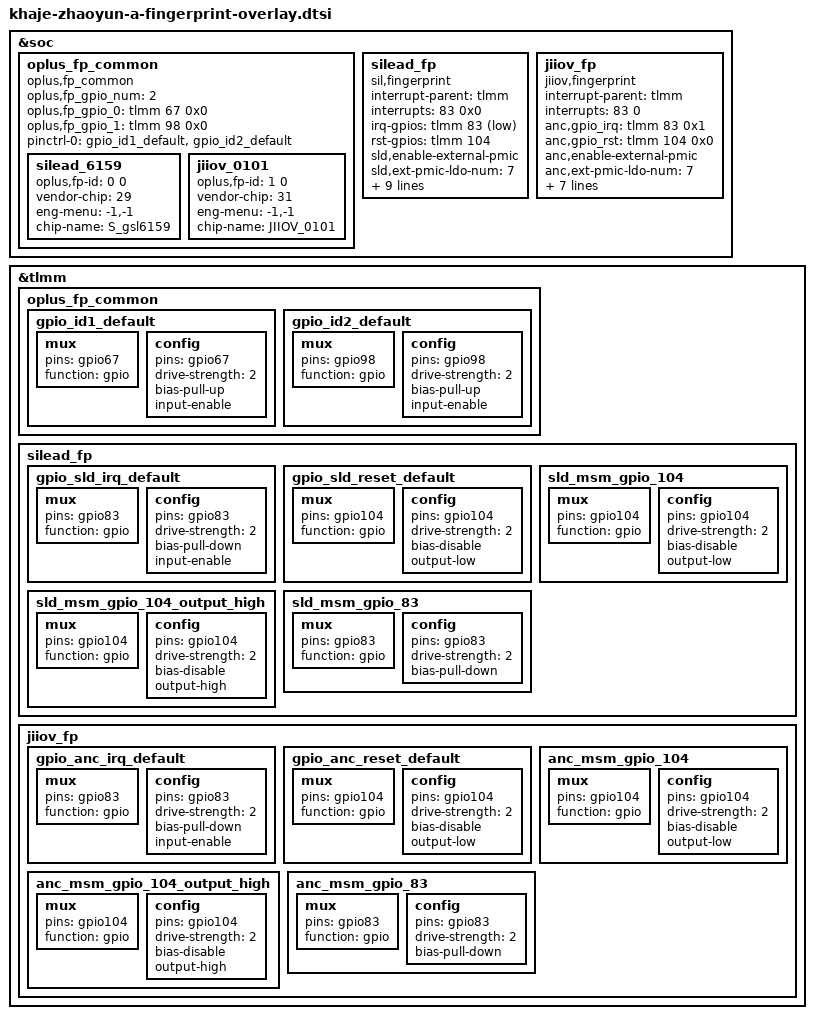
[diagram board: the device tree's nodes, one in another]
// SPDX-License-Identifier: GPL-2.0-only
/*
 * Copyright (C) 2018-2020 Oplus. All rights reserved.
 */


&soc {
	oplus_fp_common {
		status = "okay";
		compatible = "oplus,fp_common";
		oplus,fp_gpio_num = <2>;
		oplus,fp_gpio_0 = <&tlmm 67 0x0>;
		oplus,fp_gpio_1 = <&tlmm 98 0x0>;
		pinctrl-names = "default";
		pinctrl-0 = <&gpio_id1_default &gpio_id2_default>;
		silead_6159 {
			oplus,fp-id = <0 0>; /* fp id mapping table */
			vendor-chip = <29>; /* please refer to the struct fp_vendor_t in oppo_fp_commmon.n */
			eng-menu = "-1,-1"; /* represents SNR, inclination test item in engineer menu, and 0/1 means off/on */
			chip-name = "S_gsl6159";  /* /proc/fp_id, will be displayed in engineer menu  */
		};
		jiiov_0101 {
			oplus,fp-id = <1 0>; // fp id mapping table
			vendor-chip = <31>; // please refer to the struct fp_vendor_t in oplus_fp_commmon.n
			eng-menu = "-1,-1"; // represents SNR, inclination test item in engineer menu, and 0/1 means off/on
			chip-name = "JIIOV_0101";  // /proc/fp_id, will be displayed in engineer menu
		};
	};
};

&tlmm {
	oplus_fp_common {
		gpio_id1_default: gpio_id1_default {
			mux {
				pins = "gpio67";
				function = "gpio";
			};
			config {
				pins = "gpio67";
				drive-strength = <2>;
				bias-pull-up;
				input-enable;
			};
		};
		gpio_id2_default: gpio_id2_default {
			mux {
				pins = "gpio98";
				function = "gpio";
			};
			config {
				pins = "gpio98";
				drive-strength = <2>;
				bias-pull-up;
				input-enable;
			};
		};
	};
};



&soc {
	silead_fp {
		status = "okay";
		compatible = "sil,fingerprint";
		interrupt-parent = <&tlmm>;
		interrupts = <83 0x0>;
		irq-gpios = <&tlmm 83 0x1>;
		rst-gpios = <&tlmm 104 0x0>;
		//avdd-supply = <&L7P>;
		sld,enable-external-pmic;
		sld,ext-pmic-ldo-num = <7>;
		sld,ext-pmic-ldo-mv-max = <3000>;
		sld,ext-pmic-ldo-mv-min = <0>;
		spi-max-frequency = <4800000>;
		qcom,qup-id = <6>;
		pinctrl-names = "default", "sld_reset_reset", "sld_reset_active", "sld_irq_active";
		pinctrl-0 = <&gpio_sld_irq_default>, <&gpio_sld_reset_default>;
		pinctrl-1 = <&sld_msm_gpio_104>;
		pinctrl-2 = <&sld_msm_gpio_104_output_high>;
		pinctrl-3 = <&sld_msm_gpio_83>;
	};
};


&tlmm {
	silead_fp {
		gpio_sld_irq_default: gpio_sld_irq_default {
			mux {
				pins = "gpio83";
				function = "gpio";
			};
			config {
				pins = "gpio83";
				drive-strength = <2>;
				bias-pull-down;
				input-enable;
			};
		};
		gpio_sld_reset_default: gpio_sld_reset_default {
			mux {
				pins = "gpio104";
				function = "gpio";
			};
			config {
				pins = "gpio104";
				drive-strength = <2>;
				bias-disable;
				output-low;
			};
		};
		sld_msm_gpio_104: sld_msm_gpio_104 {
			mux {
				pins = "gpio104";
				function = "gpio";
			};
			config {
				pins = "gpio104";
				drive-strength = <2>;
				bias-disable;
				output-low;
			};
		};
		// GPIO_104 : FP_RESET_N, state device active
		sld_msm_gpio_104_output_high: sld_msm_gpio_104_output_high {
			mux {
				pins = "gpio104";
				function = "gpio";
			};
			config {
				pins = "gpio104";
				drive-strength = <2>;
				bias-disable;
				output-high;
			};
		};
		// GPIO_83 : FP_INT_N
		sld_msm_gpio_83: sld_msm_gpio_83 {
			mux {
				pins = "gpio83";
				function = "gpio";
			};
			config {
				pins = "gpio83";
				drive-strength = <2>;
				bias-pull-down;
			};
		};
	};
};



&soc {
	jiiov_fp {
		status = "okay";
		compatible = "jiiov,fingerprint";
		interrupt-parent = <&tlmm>;
		interrupts = <83 0>;
		anc,gpio_irq = <&tlmm 83 0x1>;
		anc,gpio_rst = <&tlmm 104 0x0>;
		anc,enable-external-pmic;
		anc,ext-pmic-ldo-num = <7>;
		anc,ext-pmic-ldo-mv-max = <3000>;
		anc,ext-pmic-ldo-mv-min = <0>;
		pinctrl-names = "default", "anc_reset_reset", "anc_reset_active", "anc_irq_active";
		pinctrl-0 = <&gpio_anc_irq_default>, <&gpio_anc_reset_default>;
		pinctrl-1 = <&anc_msm_gpio_104>;
		pinctrl-2 = <&anc_msm_gpio_104_output_high>;
		pinctrl-3 = <&anc_msm_gpio_83>;
	};
};


&tlmm {
	jiiov_fp {
		gpio_anc_irq_default: gpio_anc_irq_default {
			mux {
				pins = "gpio83";
				function = "gpio";
			};
			config {
				pins = "gpio83";
				drive-strength = <2>;
				bias-pull-down;
				input-enable;
			};
		};
		gpio_anc_reset_default: gpio_anc_reset_default {
			mux {
				pins = "gpio104";
				function = "gpio";
			};
			config {
				pins = "gpio104";
				drive-strength = <2>;
				bias-disable;
				output-low;
			};
		};
		anc_msm_gpio_104: anc_msm_gpio_104 {
			mux {
				pins = "gpio104";
				function = "gpio";
			};
			config {
				pins = "gpio104";
				drive-strength = <2>;
				bias-disable;
				output-low;
			};
		};
		// GPIO_104 : FP_RESET_N, state device active
		anc_msm_gpio_104_output_high: anc_msm_gpio_104_output_high {
			mux {
				pins = "gpio104";
				function = "gpio";
			};
			config {
				pins = "gpio104";
				drive-strength = <2>;
				bias-disable;
				output-high;
			};
		};
		// GPIO_83 : FP_INT_N
		anc_msm_gpio_83: anc_msm_gpio_83 {
			mux {
				pins = "gpio83";
				function = "gpio";
			};
			config {
				pins = "gpio83";
				drive-strength = <2>;
				bias-pull-down;
			};
		};
	};
};
